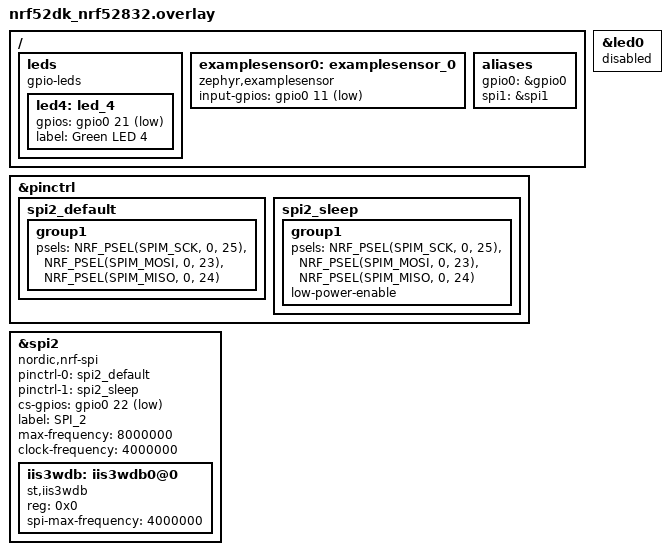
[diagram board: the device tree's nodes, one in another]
/ {
    leds {
		compatible = "gpio-leds";
		led4: led_4 {
			gpios = <&gpio0 21 GPIO_ACTIVE_LOW>;
			label = "Green LED 4";
		};
	};
    examplesensor0: examplesensor_0 {
		compatible = "zephyr,examplesensor";
		input-gpios = <&gpio0 11 (GPIO_PULL_UP | GPIO_ACTIVE_LOW)>;
	};
	aliases {
		gpio0 = &gpio0;
		spi1 = &spi1;
	};
};

&led0 {
    status = "disabled";
};

&pinctrl {
	spi2_default: spi2_default {
		group1 {
			psels = <NRF_PSEL(SPIM_SCK, 0, 25)>,
					<NRF_PSEL(SPIM_MOSI, 0, 23)>,
					<NRF_PSEL(SPIM_MISO, 0, 24)>;
		};
	};

	spi2_sleep: spi2_sleep {
		group1 {
			psels = <NRF_PSEL(SPIM_SCK, 0, 25)>,
					<NRF_PSEL(SPIM_MOSI, 0, 23)>,
					<NRF_PSEL(SPIM_MISO, 0, 24)>;
			low-power-enable;
		};
	};
};

&spi2 {
	compatible = "nordic,nrf-spi";
	status = "okay";
	pinctrl-0 = <&spi2_default>;
	pinctrl-1 = <&spi2_sleep>;
	cs-gpios = <&gpio0 22 GPIO_ACTIVE_LOW>;
	label = "SPI_2";
	max-frequency = <8000000>;
	clock-frequency = < 4000000 >; //115200
	
	iis3wdb: iis3wdb0@0 {
		compatible = "st,iis3wdb";
		reg = < 0x0 >;
		spi-max-frequency = < 4000000 >;//0x7a1200 
	};
	
};
